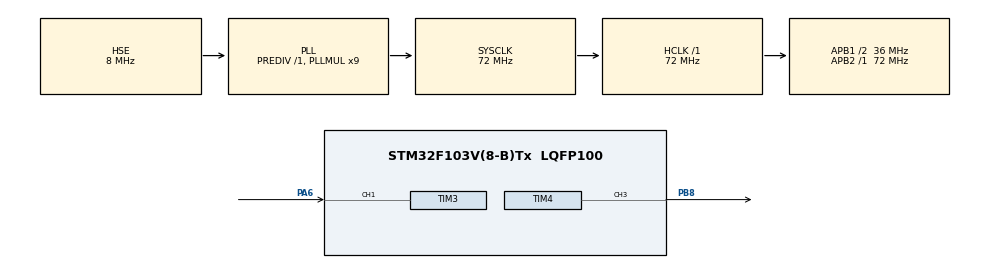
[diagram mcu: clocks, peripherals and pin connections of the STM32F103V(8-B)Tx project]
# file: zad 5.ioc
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Dma.Request0=TIM4_CH3
Dma.TIM4_CH3.0.Direction=DMA_PERIPH_TO_MEMORY
Dma.TIM4_CH3.0.Instance=DMA1_Channel5
Dma.TIM4_CH3.0.MemDataAlignment=DMA_MDATAALIGN_HALFWORD
Dma.TIM4_CH3.0.MemInc=DMA_MINC_DISABLE
Dma.TIM4_CH3.0.Mode=DMA_CIRCULAR
Dma.TIM4_CH3.0.PeriphDataAlignment=DMA_PDATAALIGN_HALFWORD
Dma.TIM4_CH3.0.PeriphInc=DMA_PINC_DISABLE
Dma.TIM4_CH3.0.Priority=DMA_PRIORITY_LOW
Mcu.Family=STM32F1
Mcu.Name=STM32F103V(8-B)Tx
Mcu.Package=LQFP100
NVIC.DMA1_Channel5_IRQn=true\:0\:0\:false\:false\:true\:false\:true\:true
NVIC.PriorityGroup=NVIC_PRIORITYGROUP_4
OSC_IN.Mode=HSE-External-Oscillator
OSC_IN.Signal=RCC_OSC_IN
OSC_OUT.Mode=HSE-External-Oscillator
OSC_OUT.Signal=RCC_OSC_OUT
PA13.Mode=JTAG_5_pins
PA13.Signal=SYS_JTMS-SWDIO
PA14.Mode=JTAG_5_pins
PA14.Signal=SYS_JTCK-SWCLK
PA15.Mode=JTAG_5_pins
PA15.Signal=SYS_JTDI
PA6.Signal=S_TIM3_CH1
PB3.Mode=JTAG_5_pins
PB3.Signal=SYS_JTDO-TRACESWO
PB4.Mode=JTAG_5_pins
PB4.Signal=SYS_NJTRST
PB8.Signal=S_TIM4_CH3
PC14-OSC32_IN.Mode=LSE-External-Oscillator
PC14-OSC32_IN.Signal=RCC_OSC32_IN
PC15-OSC32_OUT.Mode=LSE-External-Oscillator
PC15-OSC32_OUT.Signal=RCC_OSC32_OUT
ProjectManager.HeapSize=0x200
ProjectManager.StackSize=0x400
ProjectManager.TargetToolchain=MDK-ARM V5.32
RCC.AHBFreq_Value=72000000
RCC.APB1CLKDivider=RCC_HCLK_DIV2
RCC.APB1Freq_Value=36000000
RCC.APB1TimFreq_Value=72000000
RCC.APB2Freq_Value=72000000
RCC.APB2TimFreq_Value=72000000
RCC.HCLKFreq_Value=72000000
RCC.PLLMUL=RCC_PLL_MUL9
RCC.PLLSourceVirtual=RCC_PLLSOURCE_HSE
RCC.SYSCLKFreq_VALUE=72000000
RCC.SYSCLKSource=RCC_SYSCLKSOURCE_PLLCLK
RCC.USBFreq_Value=72000000
SH.S_TIM3_CH1.0=TIM3_CH1,PWM_Input_1
SH.S_TIM4_CH3.0=TIM4_CH3,PWM Generation3 CH3
TIM3.Period=1999
TIM3.Prescaler=359
TIM4.Channel-PWM\ Generation3\ CH3=TIM_CHANNEL_3
TIM4.Period=4999
TIM4.Prescaler=14399
TIM4.Pulse-PWM\ Generation3\ CH3=2499
VP_TIM3_VS_ClockSourceINT.Mode=Internal
VP_TIM4_VS_ClockSourceINT.Mode=Internal
board=custom

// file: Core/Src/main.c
/* USER CODE BEGIN Header */
/**
  ******************************************************************************
  * @file           : main.c
  * @brief          : Main program body
  ******************************************************************************
  * @attention
  *
  * Copyright (c) 2023 STMicroelectronics.
  * All rights reserved.
  *
  * This software is licensed under terms that can be found in the LICENSE file
  * in the root directory of this software component.
  * If no LICENSE file comes with this software, it is provided AS-IS.
  *
  ******************************************************************************
  */
/* USER CODE END Header */
#include "main.h"

/* USER CODE BEGIN Includes */
#include "lcd4bit.h"

/* USER CODE END Includes */

/* USER CODE BEGIN PD */
#define PA0 *((volatile unsigned long*) 0x42210100)
#define PA1 *((volatile unsigned long*) 0x42210104)
#define PA2 *((volatile unsigned long*) 0x42210108)
#define PA3 *((volatile unsigned long*) 0x4221010C)

/* USER CODE END PD */

TIM_HandleTypeDef htim3;
TIM_HandleTypeDef htim4;
DMA_HandleTypeDef hdma_tim4_ch3;

/* USER CODE BEGIN PV */
volatile uint32_t PWM_Buff=0;
Lcd_PortType ports[] = {GPIOC, GPIOC, GPIOC, GPIOC};
Lcd_PinType pins[] = {GPIO_PIN_3, GPIO_PIN_2, GPIO_PIN_1, GPIO_PIN_0};
Lcd_HandleTypeDef lcd;
int DC;
char LL[10];
volatile uint16_t InputPWMPeriod_cycles; // Czas trwania calego okresu sygnalu [w cyklach zegara]
volatile uint16_t InputPWMPeriod_miliseconds; // Czas trwania calego okresu sygnalu [w milisekundach]
volatile uint16_t InputPWMDuty_cycles; // Czas trwania stanu wysokiego [w cyklach zegara]
volatile uint16_t InputPWMDuty_percent; // Wspolczynnik wypelnienia sygnalu PWM [w procentach]
const uint16_t InputTimerResolution_cycles = 2000; // Rozdzielczosc zegara odczytujacego sygnal PWM [w cyklach zegara]
const uint16_t InputTimerPeriodDuration_miliseconds = 20; // Czas trwania jednego okresu timera odczytuja
/* USER CODE END PV */

void SystemClock_Config(void);
static void MX_GPIO_Init(void);
static void MX_DMA_Init(void);
static void MX_TIM4_Init(void);
static void MX_TIM3_Init(void);

int main(void)
{

  /* MCU Configuration--------------------------------------------------------*/

  /* Reset of all peripherals, Initializes the Flash interface and the Systick. */
  HAL_Init();

  /* Configure the system clock */
  SystemClock_Config();

  /* Initialize all configured peripherals */
  MX_GPIO_Init();
  MX_DMA_Init();
  MX_TIM4_Init();
  MX_TIM3_Init();
  /* USER CODE BEGIN 2 */
  HAL_TIM_PWM_Start_DMA(&htim4, TIM_CHANNEL_3,&PWM_Buff,1);
	lcd = Lcd_create(ports, pins, GPIOC, GPIO_PIN_12, GPIOC, GPIO_PIN_10, LCD_4_BIT_MODE);
	HAL_TIM_IC_Start(&htim3, TIM_CHANNEL_1);
	HAL_TIM_IC_Start(&htim3, TIM_CHANNEL_2);
  /* USER CODE END 2 */

  /* Infinite loop */
  /* USER CODE BEGIN WHILE */
  while (1)
  {
			if (PA0==RESET)
			{
      if (PWM_Buff<5000)
				PWM_Buff=PWM_Buff+500;
			DC=PWM_Buff*100/5000;
			sprintf(LL,"%d",DC );
			Lcd_cursor(&lcd,0,0);
			Lcd_string(&lcd,LL);

			HAL_Delay(500);
			};
		if (PA1==RESET)
			{
      if (PWM_Buff>0)
				PWM_Buff=PWM_Buff-500;
			DC=PWM_Buff*100/5000;
			sprintf(LL,"%d",DC );
			Lcd_cursor(&lcd,0,0);
			Lcd_string(&lcd,LL);
			HAL_Delay(500);
			};
    /* USER CODE END WHILE */

    /* USER CODE BEGIN 3 */
		// odczytanie dlugosci trwania okresu sygnalu (w cyklach zegara)
		InputPWMPeriod_cycles = HAL_TIM_ReadCapturedValue(&htim3, TIM_CHANNEL_1) + 1;

		// odczytanie dlugosci trwania stanu wysokiego w sygnale (w cyklach zegara)
		InputPWMDuty_cycles = HAL_TIM_ReadCapturedValue(&htim3, TIM_CHANNEL_2) + 1;

		// Przeliczenie dlugosci trwania okresu sygnalu na milisekundy
		InputPWMPeriod_miliseconds = ((InputPWMPeriod_cycles* InputTimerPeriodDuration_miliseconds)	/ (InputTimerResolution_cycles));

		// Obliczenie procentu wypelnienia sygnalu PWM
		InputPWMDuty_percent = (InputPWMDuty_cycles) * 100/ (InputPWMPeriod_cycles);
		sprintf(LL,"%d",InputPWMPeriod_miliseconds );
		Lcd_cursor(&lcd,1,0);
		Lcd_string(&lcd,LL);
		sprintf(LL,"%d",InputPWMDuty_percent );
		Lcd_cursor(&lcd,1,8);
		Lcd_string(&lcd,LL);

  }
  /* USER CODE END 3 */
}

void SystemClock_Config(void)
{
  RCC_OscInitTypeDef RCC_OscInitStruct = {0};
  RCC_ClkInitTypeDef RCC_ClkInitStruct = {0};

  /** Initializes the RCC Oscillators according to the specified parameters
  * in the RCC_OscInitTypeDef structure.
  */
  RCC_OscInitStruct.OscillatorType = RCC_OSCILLATORTYPE_HSE;
  RCC_OscInitStruct.HSEState = RCC_HSE_ON;
  RCC_OscInitStruct.HSEPredivValue = RCC_HSE_PREDIV_DIV1;
  RCC_OscInitStruct.HSIState = RCC_HSI_ON;
  RCC_OscInitStruct.PLL.PLLState = RCC_PLL_ON;
  RCC_OscInitStruct.PLL.PLLSource = RCC_PLLSOURCE_HSE;
  RCC_OscInitStruct.PLL.PLLMUL = RCC_PLL_MUL9;
  if (HAL_RCC_OscConfig(&RCC_OscInitStruct) != HAL_OK)
  {
    Error_Handler();
  }

  /** Initializes the CPU, AHB and APB buses clocks
  */
  RCC_ClkInitStruct.ClockType = RCC_CLOCKTYPE_HCLK|RCC_CLOCKTYPE_SYSCLK
                              |RCC_CLOCKTYPE_PCLK1|RCC_CLOCKTYPE_PCLK2;
  RCC_ClkInitStruct.SYSCLKSource = RCC_SYSCLKSOURCE_PLLCLK;
  RCC_ClkInitStruct.AHBCLKDivider = RCC_SYSCLK_DIV1;
  RCC_ClkInitStruct.APB1CLKDivider = RCC_HCLK_DIV2;
  RCC_ClkInitStruct.APB2CLKDivider = RCC_HCLK_DIV1;

  if (HAL_RCC_ClockConfig(&RCC_ClkInitStruct, FLASH_LATENCY_2) != HAL_OK)
  {
    Error_Handler();
  }
}

static void MX_TIM3_Init(void)
{

  TIM_ClockConfigTypeDef sClockSourceConfig = {0};
  TIM_SlaveConfigTypeDef sSlaveConfig = {0};
  TIM_IC_InitTypeDef sConfigIC = {0};
  TIM_MasterConfigTypeDef sMasterConfig = {0};

  htim3.Instance = TIM3;
  htim3.Init.Prescaler = 359;
  htim3.Init.CounterMode = TIM_COUNTERMODE_UP;
  htim3.Init.Period = 1999;
  htim3.Init.ClockDivision = TIM_CLOCKDIVISION_DIV1;
  htim3.Init.AutoReloadPreload = TIM_AUTORELOAD_PRELOAD_DISABLE;
  if (HAL_TIM_Base_Init(&htim3) != HAL_OK)
  {
    Error_Handler();
  }
  sClockSourceConfig.ClockSource = TIM_CLOCKSOURCE_INTERNAL;
  if (HAL_TIM_ConfigClockSource(&htim3, &sClockSourceConfig) != HAL_OK)
  {
    Error_Handler();
  }
  if (HAL_TIM_IC_Init(&htim3) != HAL_OK)
  {
    Error_Handler();
  }
  sSlaveConfig.SlaveMode = TIM_SLAVEMODE_RESET;
  sSlaveConfig.InputTrigger = TIM_TS_TI1FP1;
  sSlaveConfig.TriggerPolarity = TIM_INPUTCHANNELPOLARITY_RISING;
  sSlaveConfig.TriggerPrescaler = TIM_ICPSC_DIV1;
  sSlaveConfig.TriggerFilter = 0;
  if (HAL_TIM_SlaveConfigSynchro(&htim3, &sSlaveConfig) != HAL_OK)
  {
    Error_Handler();
  }
  sConfigIC.ICPolarity = TIM_INPUTCHANNELPOLARITY_RISING;
  sConfigIC.ICSelection = TIM_ICSELECTION_DIRECTTI;
  sConfigIC.ICPrescaler = TIM_ICPSC_DIV1;
  sConfigIC.ICFilter = 0;
  if (HAL_TIM_IC_ConfigChannel(&htim3, &sConfigIC, TIM_CHANNEL_1) != HAL_OK)
  {
    Error_Handler();
  }
  sConfigIC.ICPolarity = TIM_INPUTCHANNELPOLARITY_FALLING;
  sConfigIC.ICSelection = TIM_ICSELECTION_INDIRECTTI;
  if (HAL_TIM_IC_ConfigChannel(&htim3, &sConfigIC, TIM_CHANNEL_2) != HAL_OK)
  {
    Error_Handler();
  }
  sMasterConfig.MasterOutputTrigger = TIM_TRGO_RESET;
  sMasterConfig.MasterSlaveMode = TIM_MASTERSLAVEMODE_DISABLE;
  if (HAL_TIMEx_MasterConfigSynchronization(&htim3, &sMasterConfig) != HAL_OK)
  {
    Error_Handler();
  }

}

static void MX_TIM4_Init(void)
{

  TIM_ClockConfigTypeDef sClockSourceConfig = {0};
  TIM_MasterConfigTypeDef sMasterConfig = {0};
  TIM_OC_InitTypeDef sConfigOC = {0};

  htim4.Instance = TIM4;
  htim4.Init.Prescaler = 14399;
  htim4.Init.CounterMode = TIM_COUNTERMODE_UP;
  htim4.Init.Period = 4999;
  htim4.Init.ClockDivision = TIM_CLOCKDIVISION_DIV1;
  htim4.Init.AutoReloadPreload = TIM_AUTORELOAD_PRELOAD_DISABLE;
  if (HAL_TIM_Base_Init(&htim4) != HAL_OK)
  {
    Error_Handler();
  }
  sClockSourceConfig.ClockSource = TIM_CLOCKSOURCE_INTERNAL;
  if (HAL_TIM_ConfigClockSource(&htim4, &sClockSourceConfig) != HAL_OK)
  {
    Error_Handler();
  }
  if (HAL_TIM_PWM_Init(&htim4) != HAL_OK)
  {
    Error_Handler();
  }
  sMasterConfig.MasterOutputTrigger = TIM_TRGO_RESET;
  sMasterConfig.MasterSlaveMode = TIM_MASTERSLAVEMODE_DISABLE;
  if (HAL_TIMEx_MasterConfigSynchronization(&htim4, &sMasterConfig) != HAL_OK)
  {
    Error_Handler();
  }
  sConfigOC.OCMode = TIM_OCMODE_PWM1;
  sConfigOC.Pulse = 2499;
  sConfigOC.OCPolarity = TIM_OCPOLARITY_HIGH;
  sConfigOC.OCFastMode = TIM_OCFAST_DISABLE;
  if (HAL_TIM_PWM_ConfigChannel(&htim4, &sConfigOC, TIM_CHANNEL_3) != HAL_OK)
  {
    Error_Handler();
  }
  HAL_TIM_MspPostInit(&htim4);

}

static void MX_DMA_Init(void)
{

  /* DMA controller clock enable */
  __HAL_RCC_DMA1_CLK_ENABLE();

  /* DMA interrupt init */
  /* DMA1_Channel5_IRQn interrupt configuration */
  HAL_NVIC_SetPriority(DMA1_Channel5_IRQn, 0, 0);
  HAL_NVIC_EnableIRQ(DMA1_Channel5_IRQn);

}

static void MX_GPIO_Init(void)
{

  /* GPIO Ports Clock Enable */
  __HAL_RCC_GPIOC_CLK_ENABLE();
  __HAL_RCC_GPIOA_CLK_ENABLE();
  __HAL_RCC_GPIOB_CLK_ENABLE();

}

void Error_Handler(void)
{
  __disable_irq();
  while (1)
  {
  }
}
